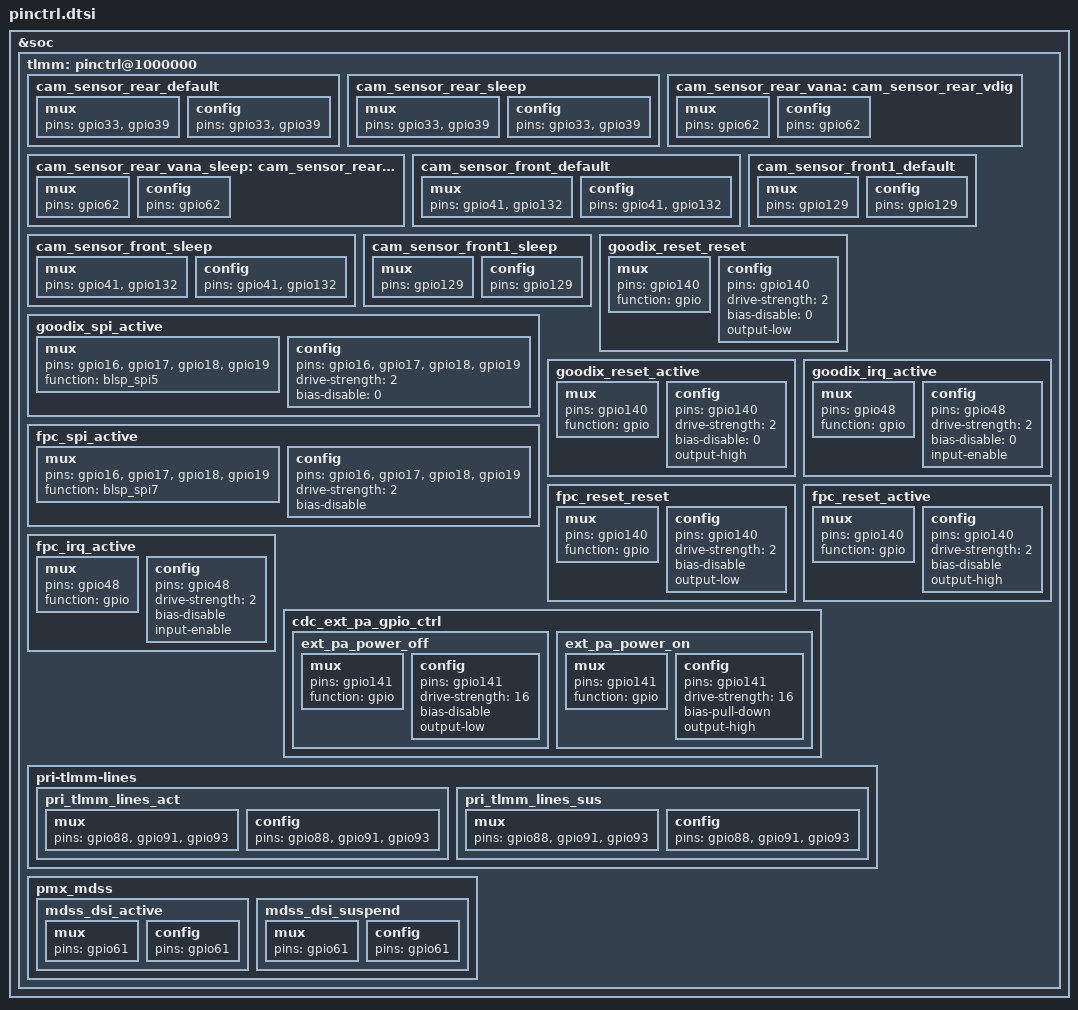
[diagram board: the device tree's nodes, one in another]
&soc {
	tlmm: pinctrl@1000000 {
		cam_sensor_rear_default: cam_sensor_rear_default {
			/* RESET, STANDBY */
			mux {
				pins = "gpio33", "gpio39";
			};

			config {
				pins = "gpio33","gpio39";
			};
		};

		cam_sensor_rear_sleep: cam_sensor_rear_sleep {
			/* RESET, STANDBY */
			mux {
				pins = "gpio33","gpio39";
			};

			config {
				pins = "gpio33","gpio39";
			};
		};

		/delete-node/ cam_sensor_ir_cut_default;
		/delete-node/ cam_sensor_ir_cut_sleep;
		/delete-node/ cam_sensor_rear_default1;
		/delete-node/ cam_sensor_rear_sleep1;

		cam_sensor_rear_vana: cam_sensor_rear_vdig {
			/* VDIG */
			mux {
				pins = "gpio62";
			};

			config {
				pins = "gpio62";
			};
		};

		cam_sensor_rear_vana_sleep: cam_sensor_rear_vdig_sleep {
			/* VDIG */
			mux {
				pins = "gpio62";
			};

			config {
				pins = "gpio62";
			};
		};

		/delete-node/ cam_sensor_rear_vdig1;
		/delete-node/ cam_sensor_rear_vdig_sleep1;

		cam_sensor_front_default: cam_sensor_front_default {
			/* RESET, STANDBY */
			mux {
				pins = "gpio41","gpio132";
			};

			config {
				pins = "gpio41","gpio132";
			};
		};

		cam_sensor_front_sleep: cam_sensor_front_sleep {
			/* RESET, STANDBY */
			mux {
				pins = "gpio41","gpio132";
			};

			config {
				pins = "gpio41","gpio132";
			};
		};

		cam_sensor_front1_default: cam_sensor_front1_default {
			/* RESET, STANDBY */
			mux {
				pins = "gpio129";
			};

			config {
				pins = "gpio129";
			};
		};

		cam_sensor_front1_sleep: cam_sensor_front1_sleep {
			/* RESET, STANDBY */
			mux {
				pins = "gpio129";
			};

			config {
				pins = "gpio129";
			};
		};

		goodix_spi_active: goodix_spi_active{
			mux {
				pins = "gpio16", "gpio17", "gpio18", "gpio19";
				function = "blsp_spi5";
			};
			config {
				pins = "gpio16", "gpio17", "gpio18", "gpio19";
				drive-strength = <2>;
				bias-disable = <0>;
			};
		};
		goodix_reset_reset: goodix_reset_reset{
			mux {
				pins = "gpio140";
				function = "gpio";
			};
			config {
				pins = "gpio140";
				drive-strength = <2>;
				bias-disable = <0>;
				output-low;
			};
		};
		goodix_reset_active: goodix_reset_active{
			mux {
				pins = "gpio140";
				function = "gpio";
			};
			config {
				pins = "gpio140";
				drive-strength = <2>;
				bias-disable = <0>;
				output-high;
			};
		};
		goodix_irq_active: goodix_irq_active {
			mux {
				pins = "gpio48";
				function = "gpio";
			};
			config {
				pins = "gpio48";
				drive-strength = <2>;
				bias-disable = <0>;
				input-enable;
			};
		};

		fpc_spi_active: fpc_spi_active {
			mux {
				pins = "gpio16", "gpio17", "gpio18", "gpio19";
				function = "blsp_spi7";
			};

			config {
				pins = "gpio16", "gpio17", "gpio18", "gpio19";
				drive-strength = <2>;
				bias-disable;
			};
		};
		fpc_reset_reset: fpc_reset_reset {
			mux {
				pins = "gpio140";
				function = "gpio";
			};
			config {
				pins = "gpio140";
				drive-strength = <2>;
				bias-disable;
				output-low;
			};
		};
		fpc_reset_active: fpc_reset_active {
			mux {
				pins = "gpio140";
				function = "gpio";
			};
			config {
				pins = "gpio140";
				drive-strength = <2>;
				bias-disable;
				output-high;
			};
		};
		fpc_irq_active: fpc_irq_active {
			mux {
				pins = "gpio48";
				function = "gpio";
			};
			config {
				pins = "gpio48";
				drive-strength = <2>;
				bias-disable;
				input-enable;
			};
		};

		cdc_ext_pa_gpio_ctrl {
			ext_pa_power_off:ext_pa_power_off{
				mux {
					pins = "gpio141";
					function = "gpio";
				};
				config {
					pins = "gpio141";
					drive-strength = <16>;
					bias-disable;
					output-low;
				};
			};
			ext_pa_power_on:ext_pa_power_on{
				mux {
					pins = "gpio141";
					function = "gpio";
				};
				config {
					pins = "gpio141";
					drive-strength = <16>;
					bias-pull-down;
					output-high;
				};
			};
		};

		pri-tlmm-lines {
			pri_tlmm_lines_act: pri_tlmm_lines_act {
				mux {
					pins = "gpio88", "gpio91", "gpio93";
				};

				config {
					pins = "gpio88", "gpio91", "gpio93";
				};
			};

			pri_tlmm_lines_sus: pri_tlmm_lines_sus {
				mux {
					pins = "gpio88", "gpio91", "gpio93";
				};

				config {
					pins = "gpio88", "gpio91", "gpio93";
				};
			};
		};

		pmx_mdss {
			mdss_dsi_active: mdss_dsi_active {
				mux {
					pins = "gpio61";
				};
				config {
					pins = "gpio61";
				};
			};
			mdss_dsi_suspend: mdss_dsi_suspend {
				mux {
					pins = "gpio61";
				};
				config {
					pins = "gpio61";
				};
			};
		};
	};
};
